# psoc4100sp256kb register map
Vendor: Infineon Technologies; Series: PSOC4100Sp256KB; File version: 1.0
CPU: CM0PLUS r0p1, little endian, MPU, no FPU, VTOR, 2 interrupt priority bits, 29 interrupts
Registers are 32-bit, read-write, reset 0x0 unless marked. A register's access mark holds for its fields unless they carry their own. Offsets are from the block's base; [hi:lo] are bit positions; lines under a group give offsets from that group; {n}, {i} and the like mark numbered series.

## PERI — Peripheral Interconnect
Base 0x40010000
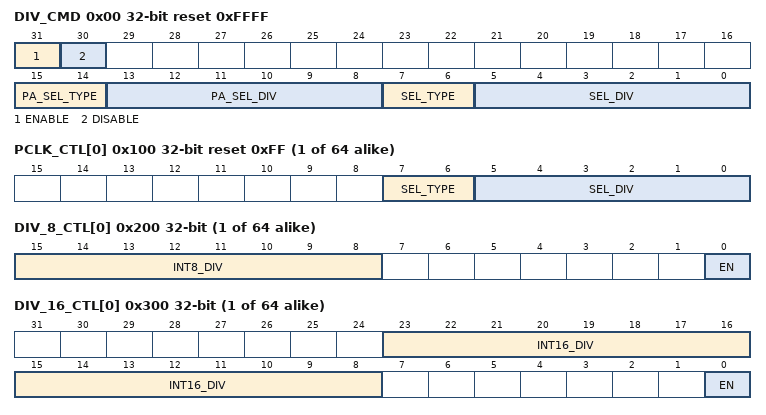
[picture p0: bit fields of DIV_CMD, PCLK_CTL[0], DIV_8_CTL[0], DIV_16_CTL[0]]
0x00 DIV_CMD reset 0xFFFF — Divider command register
  [31] ENABLE — Clock divider enable command (mutually exclusive with DISABLE). Typically, SW sets this field to '1' to enable a divider and HW sets this field to '0' to indicate that divider enabling has completed. When a divider is enabled, its integer and fractional (if present) counters are initialized to '0'. If a divider is to be re-enabled using different integer and fractional divider values, the SW should follow these steps: 0: Disable the divider using the DIV_CMD.DISABLE field. 1: Configure the divider's DIV_XXX_CTL register. 2: Enable the divider using the DIV_CMD_ENABLE field. The SEL_DIV and SEL_TYPE fields specify which divider is to be enabled. The enabled divider may be phase aligned to either 'clk_hf' (typical usage) or to ANY enabled divider. The PA_SEL_DIV and P_SEL_TYPE fields specify the reference divider. The HW sets the ENABLE field to '0' when the enabling is performed and the HW sets the DIV_XXX_CTL.EN field of the divider to '1' when the enabling is performed. Note that enabling with phase alignment to a low frequency divider takes time. E.g. To align to a divider that generates a clock of 'clk_hf'/n (with n being the integer divider value INT_DIV+1), up to n cycles may be required to perform alignment. Phase alignment to 'clk_hf' takes affect immediately. SW can set this field to '0' during phase alignment to abort the enabling process.
  [30] DISABLE — Clock divider disable command (mutually exclusive with ENABLE). SW sets this field to '1' and HW sets this field to '0'. The SEL_DIV and SEL_TYPE fields specify which divider is to be disabled. The HW sets the DISABLE field to '0' immediately and the HW sets the DIV_XXX_CTL.EN field of the divider to '0' immediately.
  [15:14] PA_SEL_TYPE — Specifies the divider type of the divider to which phase alignment is performed for the clock enable command: 0: 8.0 (integer) clock dividers. 1: 16.0 (integer) clock dividers. 2: 16.5 (fractional) clock dividers. 3: 24.5 (fractional) clock dividers.
  [13:8] PA_SEL_DIV — (PA_SEL_TYPE, PA_SEL_DIV) specifies the divider to which phase alignment is performed for the clock enable command. Any enabled divider can be used as reference. This allows all dividers to be aligned with each other, even when they are enabled at different times. If PA_SEL_DIV is '63' and 'PA_SEL_TYPE' is '3', 'clk_hf' is used as reference.
  [7:6] SEL_TYPE — Specifies the divider type of the divider on which the command is performed: 0: 8.0 (integer) clock dividers. 1: 16.0 (integer) clock dividers. 2: 16.5 (fractional) clock dividers. 3: 24.5 (fractional) clock dividers.
  [5:0] SEL_DIV — (SEL_TYPE, SEL_DIV) specifies the divider on which the command (DISABLE/ENABLE) is performed. If SEL_DIV is '63' and 'SEL_TYPE' is '3' (default/reset value), no divider is specified and no clock signal(s) are generated.
{0x100+4i} PCLK_CTL[{i}] (i=0..63) reset 0xFF — Programmable clock control register
  [7:6] SEL_TYPE — Specifies divider type: 0: 8.0 (integer) clock dividers. 1: 16.0 (integer) clock dividers. 2: 16.5 (fractional) clock dividers. 3: 24.5 (fractional) clock dividers.
  [5:0] SEL_DIV — Specifies one of the dividers of the divider type specified by SEL_TYPE. If SEL_DIV is '63' and 'SEL_TYPE' is '3' (default/reset value), no divider is specified and no clock control signal(s) are generated. When transitioning a clock between two out of phase dividers, spurious clock control signals may be generated for one 'clk_hf' cycle during this transition. These clock control signals may cause a single clock period that is smaller than any of the two divider periods. To prevent these spurious clock signals, the clock multiplexer can be disconnected (SEL_DIV is '63' and 'SEL_TYPE' is '3') for a transition time that is larger than the smaller of the two divider periods.
{0x200+4i} DIV_8_CTL[{i}] (i=0..63) — Divider control register (for 8.0 divider)
  [15:8] INT8_DIV — Integer division by (1+INT8_DIV). Allows for integer divisions in the range [1, 256]. Note: this type of divider does NOT allow for a fractional division. For the generation of a divided clock, the integer division range is restricted to [2, 256]. For the generation of a 50/50 percent duty cycle digital divided clock, the integer division range is restricted to even numbers in the range [2, 256]. The generation of a 50/50 percent duty cycle analog divided clock has no restrictions. Note that this field is retained. However, the counter that is used to implement the division is not and will be initialized by HW to '0' when transitioning from DeepSleep to Active power mode.
  [0] EN ro — Divider enabled. HW sets this field to '1' as a result of an ENABLE command. HW sets this field to '0' as a result on a DISABLE command. Note that this field is retained. As a result, the divider does NOT have to be re-enabled after transitioning from DeepSleep to Active power mode.
{0x300+4i} DIV_16_CTL[{i}] (i=0..63) — Divider control register (for 16.0 divider)
  [23:8] INT16_DIV — Integer division by (1+INT16_DIV). Allows for integer divisions in the range [1, 65,536]. Note: this type of divider does NOT allow for a fractional division. For the generation of a divided clock, the integer division range is restricted to [2, 65,536]. For the generation of a 50/50 percent duty cycle digital divided clock, the integer division range is restricted to even numbers in the range [2, 65,536]. The generation of a 50/50 percent duty cycle analog divided clock has no restrictions. Note that this field is retained. However, the counter that is used to implement the division is not and will be initialized by HW to '0' when transitioning from DeepSleep to Active power mode.
  [0] EN ro — Divider enabled. HW sets this field to '1' as a result of an ENABLE command. HW sets this field to '0' as a result on a DISABLE command. Note that this field is retained. As a result, the divider does NOT have to be re-enabled after transitioning from DeepSleep to Active power mode.
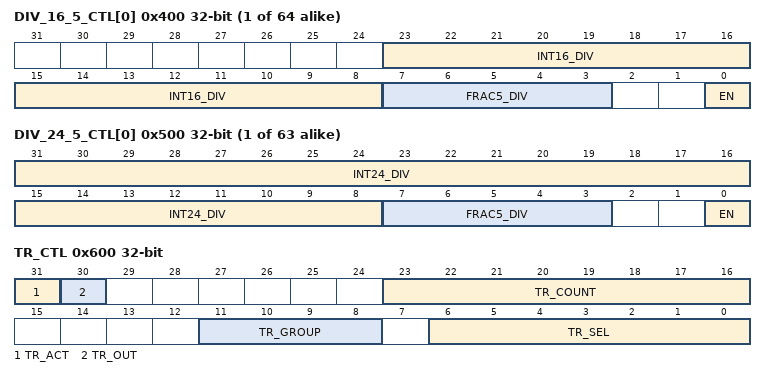
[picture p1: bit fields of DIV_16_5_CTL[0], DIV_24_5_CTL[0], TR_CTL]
{0x400+4i} DIV_16_5_CTL[{i}] (i=0..63) — Divider control register (for 16.5 divider)
  [23:8] INT16_DIV — Integer division by (1+INT16_DIV). Allows for integer divisions in the range [1, 65,536]. Note: combined with fractional division, this divider type allows for a division in the range [1, 65,536 31/32] in 1/32 increments. For the generation of a divided clock, the division range is restricted to [2, 65,536 31/32]. For the generation of a 50/50 percent duty cycle divided clock, the division range is restricted to [2, 65,536]. Note that this field is retained. However, the counter that is used to implement the division is not and will be initialized by HW to '0' when transitioning from DeepSleep to Active power mode.
  [7:3] FRAC5_DIV — Fractional division by (FRAC5_DIV/32). Allows for fractional divisions in the range [0, 31/32]. Note that fractional division results in clock jitter as some clock periods may be 1 'clk_hf' cycle longer than other clock periods. Note that this field is retained. However, the counter that is used to implement the division is not and will be initialized by HW to '0' when transitioning from DeepSleep to Active power mode.
  [0] EN ro — Divider enabled. HW sets this field to '1' as a result of an ENABLE command. HW sets this field to '0' as a result on a DISABLE command. Note that this field is retained. As a result, the divider does NOT have to be re-enabled after transitioning from DeepSleep to Active power mode.
{0x500+4i} DIV_24_5_CTL[{i}] (i=0..62) — Divider control register (for 24.5 divider)
  [31:8] INT24_DIV — Integer division by (1+INT24_DIV). Allows for integer divisions in the range [1, 16,777,216]. Note: combined with fractional division, this divider type allows for a division in the range [1, 16,777,216 31/32] in 1/32 increments. For the generation of a divided clock, the integer division range is restricted to [2, 16,777,216 31/32]. For the generation of a 50/50 percent duty cycle divided clock, the division range is restricted to [2, 16,777,216]. Note that this field is retained. However, the counter that is used to implement the division is not and will be initialized by HW to '0' when transitioning from DeepSleep to Active power mode.
  [7:3] FRAC5_DIV — Fractional division by (FRAC5_DIV/32). Allows for fractional divisions in the range [0, 31/32]. Note that fractional division results in clock jitter as some clock periods may be 1 'clk_hf' cycle longer than other clock periods. Note that this field is retained. However, the counter that is used to implement the division is not and will be initialized by HW to '0' when transitioning from DeepSleep to Active power mode.
  [0] EN ro — Divider enabled. HW sets this field to '1' as a result of an ENABLE command. HW sets this field to '0' as a result on a DISABLE command. Note that this field is retained. As a result, the divider does NOT have to be re-enabled after transitioning from DeepSleep to Active power mode.
0x600 TR_CTL — Trigger control register
  [31] TR_ACT — SW sets this field to '1' to activate (set to '1') a trigger as identified by TR_SEL and TR_OUT for TR_COUNT cycles. HW sets this field to '0' when the cycle counter is decremented to '0'. Note: a TR_COUNT value of 255 is a special case and trigger activation is under direct control of the TR_ACT field (the counter is not decremented). Note: when TR_ACT is '1', SW should not modify the other register fields. SW MUST NOT set TR_ACT bit to '1' while updating the other register bits simultaneously. At first the SW MUST update the other register bits as needed, and then set TR_ACT to '1' with a new register write.'
  [30] TR_OUT — Specifies whether trigger activation is for a specific input or output trigger of the trigger multiplexer. Activation of a specific input trigger, will result in activation of all output triggers that have the specific input trigger selected through their TR_OUT_CTL.SEL field. Activation of a specific output trigger, will result in activation of the specified TR_SEL output trigger only. '0': TR_SEL selection and trigger activation is for an input trigger to the trigger multiplexer. '1': TR_SEL selection and trigger activation is for an output trigger from the trigger multiplexer.
  [23:16] TR_COUNT — Amount of cycles a specific trigger is activated. During activation (TR_ACT is '1'), HW decrements this field to '0' using a cycle counter. During activation, SW should not modify this register field. A value of 255 is a special case: HW does NOT decrement this field to '0' and trigger activation is under direct control of TR_ACT: when TR_ACT is '1' the trigger is activated and when TR_ACT is '0' the trigger is deactivated.
  [11:8] TR_GROUP — Specifies the trigger group.
  [6:0] TR_SEL — Specifies the activated trigger when TR_ACT is '1'. TR_OUT specifies whether the activated trigger is an input trigger or output trigger to the trigger multiplexer. During activation (TR_ACT is '1'), SW should not modify this register field. If the specified trigger is not present, the trigger activation has no effect.
{0x2000+0x200*i} TR_GROUP[{i}] (i=0..4) group — Peripheral Interconnect trigger group control registers
  {0x0+4j} TR_OUT_CTL[{j}] (j=0..127) — Trigger control register
    [6:0] SEL — Specifies input trigger. This field is typically set during the setup of a chip use case scenario. Changing this field while activated triggers are present on the input triggers may result in unpredictable behavior. Note that input trigger 0 (default value) is typically connected to a constant signal level of '0', and as a result will not cause HW activation of the output trigger.

## Notices in the file
(c) 2016-2026, Infineon Technologies AG or an affiliate of
Infineon Technologies AG.
SPDX-License-Identifier: Apache-2.0
Licensed under the Apache License, Version 2.0 (the "License");
you may not use this file except in compliance with the License.
You may obtain a copy of the License at
http://www.apache.org/licenses/LICENSE-2.0
Unless required by applicable law or agreed to in writing, software
distributed under the License is distributed on an "AS IS" BASIS,
WITHOUT WARRANTIES OR CONDITIONS OF ANY KIND, either express or implied.
See the License for the specific language governing permissions and
limitations under the License.
